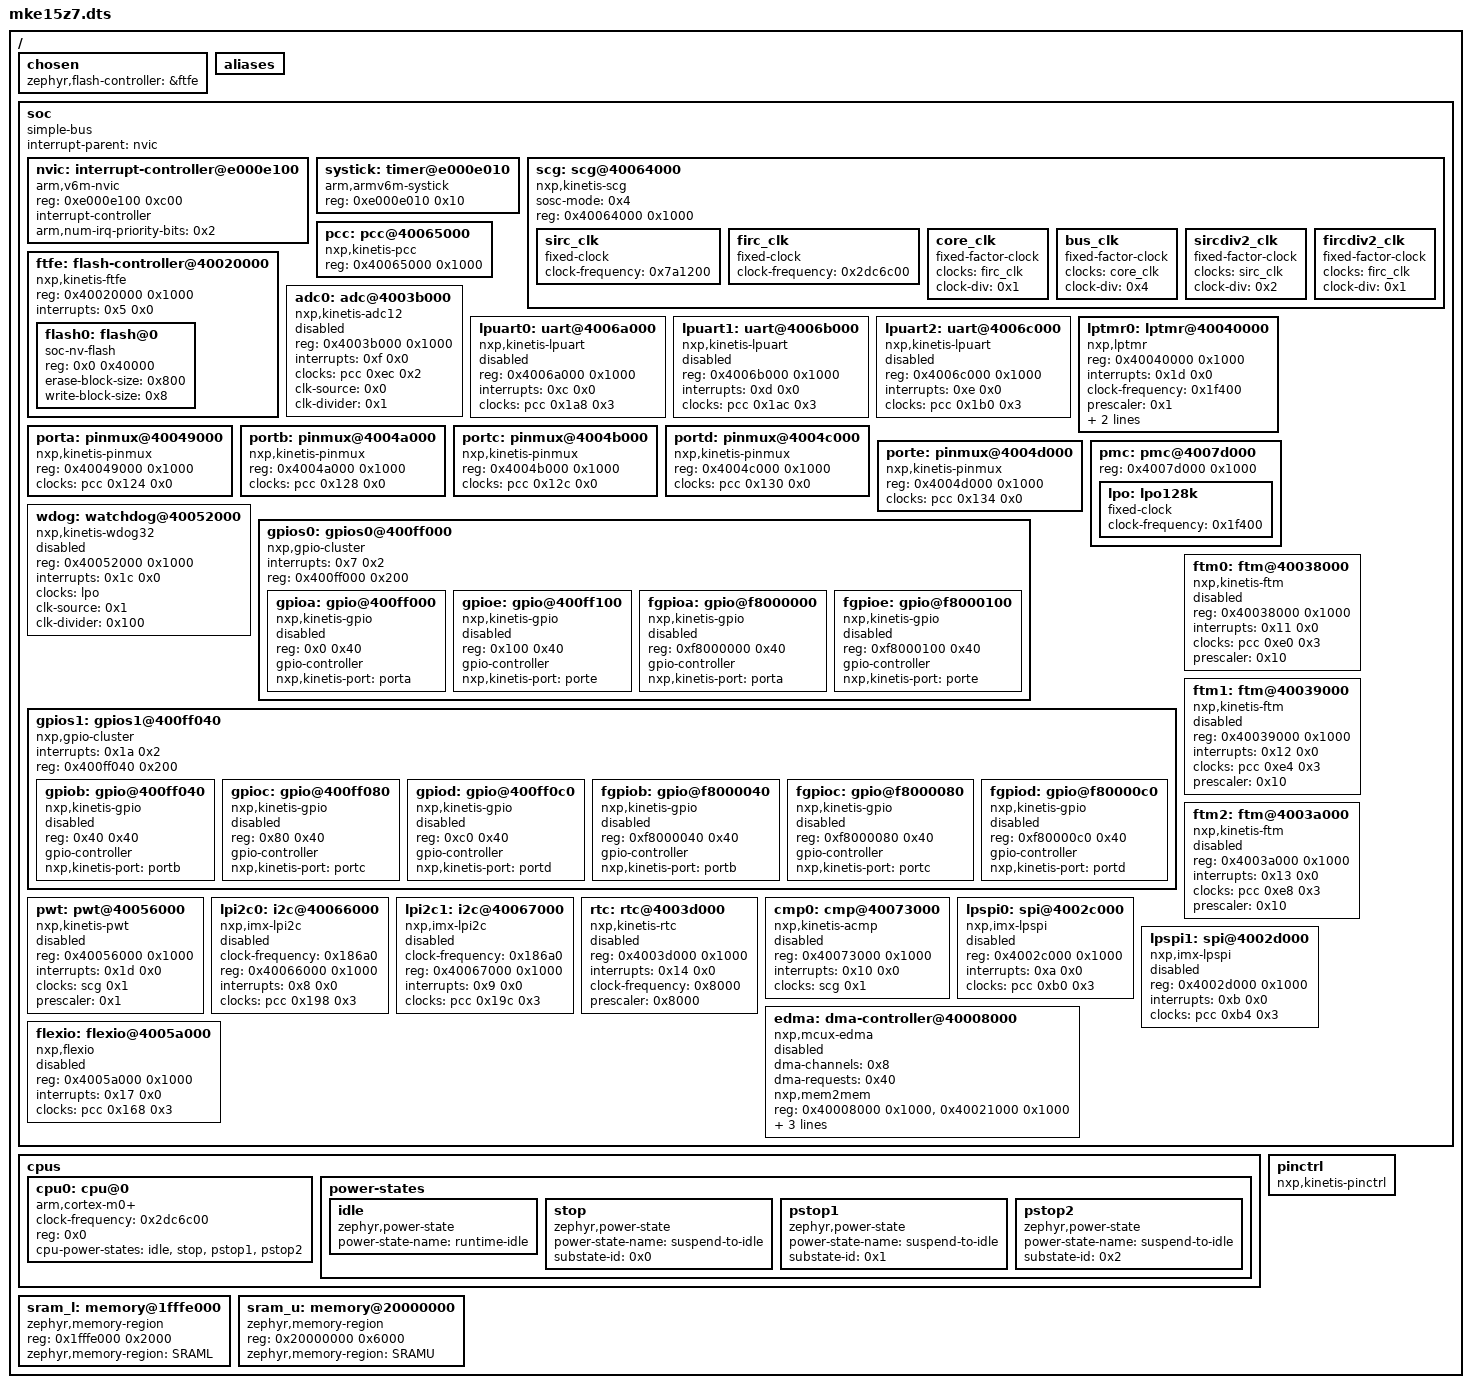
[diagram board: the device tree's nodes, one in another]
/dts-v1/;

/ {
	#address-cells = < 0x1 >;
	#size-cells = < 0x1 >;
	chosen {
		zephyr,flash-controller = &ftfe;
	};
	aliases {
	};
	soc {
		#address-cells = < 0x1 >;
		#size-cells = < 0x1 >;
		compatible = "simple-bus";
		interrupt-parent = < &nvic >;
		ranges;
		nvic: interrupt-controller@e000e100 {
			#address-cells = < 0x1 >;
			compatible = "arm,v6m-nvic";
			reg = < 0xe000e100 0xc00 >;
			interrupt-controller;
			#interrupt-cells = < 0x2 >;
			arm,num-irq-priority-bits = < 0x2 >;
			phandle = < 0x1 >;
		};
		systick: timer@e000e010 {
			compatible = "arm,armv6m-systick";
			reg = < 0xe000e010 0x10 >;
		};
		scg: scg@40064000 {
			sosc-mode = < 0x4 >;
			compatible = "nxp,kinetis-scg";
			reg = < 0x40064000 0x1000 >;
			#clock-cells = < 0x1 >;
			phandle = < 0xc >;
			sirc_clk: sirc_clk {
				compatible = "fixed-clock";
				clock-frequency = < 0x7a1200 >;
				#clock-cells = < 0x0 >;
				phandle = < 0x4 >;
			};
			firc_clk: firc_clk {
				compatible = "fixed-clock";
				clock-frequency = < 0x2dc6c00 >;
				#clock-cells = < 0x0 >;
				phandle = < 0x2 >;
			};
			core_clk: core_clk {
				compatible = "fixed-factor-clock";
				clocks = < &firc_clk >;
				clock-div = < 0x1 >;
				#clock-cells = < 0x0 >;
				phandle = < 0x3 >;
			};
			bus_clk: bus_clk {
				compatible = "fixed-factor-clock";
				clocks = < &core_clk >;
				clock-div = < 0x4 >;
				#clock-cells = < 0x0 >;
			};
			sircdiv2_clk: sircdiv2_clk {
				compatible = "fixed-factor-clock";
				clocks = < &sirc_clk >;
				clock-div = < 0x2 >;
				#clock-cells = < 0x0 >;
			};
			fircdiv2_clk: fircdiv2_clk {
				compatible = "fixed-factor-clock";
				clocks = < &firc_clk >;
				clock-div = < 0x1 >;
				#clock-cells = < 0x0 >;
			};
		};
		pcc: pcc@40065000 {
			compatible = "nxp,kinetis-pcc";
			reg = < 0x40065000 0x1000 >;
			#clock-cells = < 0x2 >;
			phandle = < 0x5 >;
		};
		ftfe: flash-controller@40020000 {
			compatible = "nxp,kinetis-ftfe";
			reg = < 0x40020000 0x1000 >;
			interrupts = < 0x5 0x0 >;
			interrupt-names = "command-complete";
			#address-cells = < 0x1 >;
			#size-cells = < 0x1 >;
			flash0: flash@0 {
				compatible = "soc-nv-flash";
				reg = < 0x0 0x40000 >;
				erase-block-size = < 0x800 >;
				write-block-size = < 0x8 >;
			};
		};
		adc0: adc@4003b000 {
			compatible = "nxp,kinetis-adc12";
			reg = < 0x4003b000 0x1000 >;
			interrupts = < 0xf 0x0 >;
			clocks = < &pcc 0xec 0x2 >;
			clk-source = < 0x0 >;
			clk-divider = < 0x1 >;
			status = "disabled";
			#io-channel-cells = < 0x1 >;
		};
		lpuart0: uart@4006a000 {
			compatible = "nxp,kinetis-lpuart";
			reg = < 0x4006a000 0x1000 >;
			interrupts = < 0xc 0x0 >;
			clocks = < &pcc 0x1a8 0x3 >;
			status = "disabled";
		};
		lpuart1: uart@4006b000 {
			compatible = "nxp,kinetis-lpuart";
			reg = < 0x4006b000 0x1000 >;
			interrupts = < 0xd 0x0 >;
			clocks = < &pcc 0x1ac 0x3 >;
			status = "disabled";
		};
		lpuart2: uart@4006c000 {
			compatible = "nxp,kinetis-lpuart";
			reg = < 0x4006c000 0x1000 >;
			interrupts = < 0xe 0x0 >;
			clocks = < &pcc 0x1b0 0x3 >;
			status = "disabled";
		};
		lptmr0: lptmr@40040000 {
			compatible = "nxp,lptmr";
			reg = < 0x40040000 0x1000 >;
			interrupts = < 0x1d 0x0 >;
			clock-frequency = < 0x1f400 >;
			prescaler = < 0x1 >;
			clk-source = < 0x1 >;
			resolution = < 0x10 >;
		};
		porta: pinmux@40049000 {
			compatible = "nxp,kinetis-pinmux";
			reg = < 0x40049000 0x1000 >;
			clocks = < &pcc 0x124 0x0 >;
			phandle = < 0x7 >;
		};
		portb: pinmux@4004a000 {
			compatible = "nxp,kinetis-pinmux";
			reg = < 0x4004a000 0x1000 >;
			clocks = < &pcc 0x128 0x0 >;
			phandle = < 0x9 >;
		};
		portc: pinmux@4004b000 {
			compatible = "nxp,kinetis-pinmux";
			reg = < 0x4004b000 0x1000 >;
			clocks = < &pcc 0x12c 0x0 >;
			phandle = < 0xa >;
		};
		portd: pinmux@4004c000 {
			compatible = "nxp,kinetis-pinmux";
			reg = < 0x4004c000 0x1000 >;
			clocks = < &pcc 0x130 0x0 >;
			phandle = < 0xb >;
		};
		porte: pinmux@4004d000 {
			compatible = "nxp,kinetis-pinmux";
			reg = < 0x4004d000 0x1000 >;
			clocks = < &pcc 0x134 0x0 >;
			phandle = < 0x8 >;
		};
		pmc: pmc@4007d000 {
			reg = < 0x4007d000 0x1000 >;
			lpo: lpo128k {
				compatible = "fixed-clock";
				clock-frequency = < 0x1f400 >;
				#clock-cells = < 0x0 >;
				phandle = < 0x6 >;
			};
		};
		wdog: watchdog@40052000 {
			compatible = "nxp,kinetis-wdog32";
			reg = < 0x40052000 0x1000 >;
			interrupts = < 0x1c 0x0 >;
			clocks = < &lpo >;
			clk-source = < 0x1 >;
			clk-divider = < 0x100 >;
			status = "disabled";
		};
		gpios0: gpios0@400ff000 {
			compatible = "nxp,gpio-cluster";
			interrupts = < 0x7 0x2 >;
			reg = < 0x400ff000 0x200 >;
			ranges = < 0x0 0x400ff000 0x200 >;
			#address-cells = < 0x1 >;
			#size-cells = < 0x1 >;
			gpioa: gpio@400ff000 {
				compatible = "nxp,kinetis-gpio";
				status = "disabled";
				reg = < 0x0 0x40 >;
				gpio-controller;
				#gpio-cells = < 0x2 >;
				nxp,kinetis-port = < &porta >;
			};
			gpioe: gpio@400ff100 {
				compatible = "nxp,kinetis-gpio";
				status = "disabled";
				reg = < 0x100 0x40 >;
				gpio-controller;
				#gpio-cells = < 0x2 >;
				nxp,kinetis-port = < &porte >;
			};
			fgpioa: gpio@f8000000 {
				compatible = "nxp,kinetis-gpio";
				status = "disabled";
				reg = < 0xf8000000 0x40 >;
				gpio-controller;
				#gpio-cells = < 0x2 >;
				nxp,kinetis-port = < &porta >;
			};
			fgpioe: gpio@f8000100 {
				compatible = "nxp,kinetis-gpio";
				status = "disabled";
				reg = < 0xf8000100 0x40 >;
				gpio-controller;
				#gpio-cells = < 0x2 >;
				nxp,kinetis-port = < &porte >;
			};
		};
		gpios1: gpios1@400ff040 {
			compatible = "nxp,gpio-cluster";
			interrupts = < 0x1a 0x2 >;
			reg = < 0x400ff040 0x200 >;
			ranges = < 0x40 0x400ff040 0x200 >;
			#address-cells = < 0x1 >;
			#size-cells = < 0x1 >;
			gpiob: gpio@400ff040 {
				compatible = "nxp,kinetis-gpio";
				status = "disabled";
				reg = < 0x40 0x40 >;
				gpio-controller;
				#gpio-cells = < 0x2 >;
				nxp,kinetis-port = < &portb >;
			};
			gpioc: gpio@400ff080 {
				compatible = "nxp,kinetis-gpio";
				status = "disabled";
				reg = < 0x80 0x40 >;
				gpio-controller;
				#gpio-cells = < 0x2 >;
				nxp,kinetis-port = < &portc >;
			};
			gpiod: gpio@400ff0c0 {
				compatible = "nxp,kinetis-gpio";
				status = "disabled";
				reg = < 0xc0 0x40 >;
				gpio-controller;
				#gpio-cells = < 0x2 >;
				nxp,kinetis-port = < &portd >;
			};
			fgpiob: gpio@f8000040 {
				compatible = "nxp,kinetis-gpio";
				status = "disabled";
				reg = < 0xf8000040 0x40 >;
				gpio-controller;
				#gpio-cells = < 0x2 >;
				nxp,kinetis-port = < &portb >;
			};
			fgpioc: gpio@f8000080 {
				compatible = "nxp,kinetis-gpio";
				status = "disabled";
				reg = < 0xf8000080 0x40 >;
				gpio-controller;
				#gpio-cells = < 0x2 >;
				nxp,kinetis-port = < &portc >;
			};
			fgpiod: gpio@f80000c0 {
				compatible = "nxp,kinetis-gpio";
				status = "disabled";
				reg = < 0xf80000c0 0x40 >;
				gpio-controller;
				#gpio-cells = < 0x2 >;
				nxp,kinetis-port = < &portd >;
			};
		};
		ftm0: ftm@40038000 {
			compatible = "nxp,kinetis-ftm";
			reg = < 0x40038000 0x1000 >;
			interrupts = < 0x11 0x0 >;
			clocks = < &pcc 0xe0 0x3 >;
			prescaler = < 0x10 >;
			status = "disabled";
		};
		ftm1: ftm@40039000 {
			compatible = "nxp,kinetis-ftm";
			reg = < 0x40039000 0x1000 >;
			interrupts = < 0x12 0x0 >;
			clocks = < &pcc 0xe4 0x3 >;
			prescaler = < 0x10 >;
			status = "disabled";
		};
		ftm2: ftm@4003a000 {
			compatible = "nxp,kinetis-ftm";
			reg = < 0x4003a000 0x1000 >;
			interrupts = < 0x13 0x0 >;
			clocks = < &pcc 0xe8 0x3 >;
			prescaler = < 0x10 >;
			status = "disabled";
		};
		pwt: pwt@40056000 {
			compatible = "nxp,kinetis-pwt";
			reg = < 0x40056000 0x1000 >;
			interrupts = < 0x1d 0x0 >;
			clocks = < &scg 0x1 >;
			prescaler = < 0x1 >;
			status = "disabled";
			#pwm-cells = < 0x3 >;
		};
		lpi2c0: i2c@40066000 {
			compatible = "nxp,imx-lpi2c";
			clock-frequency = < 0x186a0 >;
			#address-cells = < 0x1 >;
			#size-cells = < 0x0 >;
			reg = < 0x40066000 0x1000 >;
			interrupts = < 0x8 0x0 >;
			clocks = < &pcc 0x198 0x3 >;
			status = "disabled";
		};
		lpi2c1: i2c@40067000 {
			compatible = "nxp,imx-lpi2c";
			clock-frequency = < 0x186a0 >;
			#address-cells = < 0x1 >;
			#size-cells = < 0x0 >;
			reg = < 0x40067000 0x1000 >;
			interrupts = < 0x9 0x0 >;
			clocks = < &pcc 0x19c 0x3 >;
			status = "disabled";
		};
		rtc: rtc@4003d000 {
			compatible = "nxp,kinetis-rtc";
			reg = < 0x4003d000 0x1000 >;
			interrupts = < 0x14 0x0 >;
			clock-frequency = < 0x8000 >;
			prescaler = < 0x8000 >;
			status = "disabled";
		};
		cmp0: cmp@40073000 {
			compatible = "nxp,kinetis-acmp";
			reg = < 0x40073000 0x1000 >;
			interrupts = < 0x10 0x0 >;
			clocks = < &scg 0x1 >;
			status = "disabled";
			#io-channel-cells = < 0x2 >;
		};
		lpspi0: spi@4002c000 {
			compatible = "nxp,imx-lpspi";
			reg = < 0x4002c000 0x1000 >;
			interrupts = < 0xa 0x0 >;
			clocks = < &pcc 0xb0 0x3 >;
			status = "disabled";
			#address-cells = < 0x1 >;
			#size-cells = < 0x0 >;
		};
		lpspi1: spi@4002d000 {
			compatible = "nxp,imx-lpspi";
			reg = < 0x4002d000 0x1000 >;
			interrupts = < 0xb 0x0 >;
			clocks = < &pcc 0xb4 0x3 >;
			status = "disabled";
			#address-cells = < 0x1 >;
			#size-cells = < 0x0 >;
		};
		edma: dma-controller@40008000 {
			compatible = "nxp,mcux-edma";
			dma-channels = < 0x8 >;
			dma-requests = < 0x40 >;
			nxp,mem2mem;
			reg = < 0x40008000 0x1000 >, < 0x40021000 0x1000 >;
			interrupts = < 0x0 0x0 >, < 0x1 0x0 >, < 0x2 0x0 >, < 0x3 0x0 >, < 0x4 0x0 >;
			status = "disabled";
			#dma-cells = < 0x2 >;
			irq-shared-offset = < 0x4 >;
		};
		flexio: flexio@4005a000 {
			compatible = "nxp,flexio";
			reg = < 0x4005a000 0x1000 >;
			status = "disabled";
			interrupts = < 0x17 0x0 >;
			clocks = < &pcc 0x168 0x3 >;
		};
	};
	cpus {
		#address-cells = < 0x1 >;
		#size-cells = < 0x0 >;
		cpu0: cpu@0 {
			compatible = "arm,cortex-m0+";
			clock-frequency = < 0x2dc6c00 >;
			reg = < 0x0 >;
			cpu-power-states = < &idle &stop &pstop1 &pstop2 >;
		};
		power-states {
			idle: idle {
				compatible = "zephyr,power-state";
				power-state-name = "runtime-idle";
				phandle = < 0xd >;
			};
			stop: stop {
				compatible = "zephyr,power-state";
				power-state-name = "suspend-to-idle";
				substate-id = < 0x0 >;
				phandle = < 0xe >;
			};
			pstop1: pstop1 {
				compatible = "zephyr,power-state";
				power-state-name = "suspend-to-idle";
				substate-id = < 0x1 >;
				phandle = < 0xf >;
			};
			pstop2: pstop2 {
				compatible = "zephyr,power-state";
				power-state-name = "suspend-to-idle";
				substate-id = < 0x2 >;
				phandle = < 0x10 >;
			};
		};
	};
	sram_l: memory@1fffe000 {
		compatible = "zephyr,memory-region", "mmio-sram";
		reg = < 0x1fffe000 0x2000 >;
		zephyr,memory-region = "SRAML";
	};
	sram_u: memory@20000000 {
		compatible = "zephyr,memory-region", "mmio-sram";
		reg = < 0x20000000 0x6000 >;
		zephyr,memory-region = "SRAMU";
	};
	pinctrl: pinctrl {
		compatible = "nxp,kinetis-pinctrl";
	};
};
